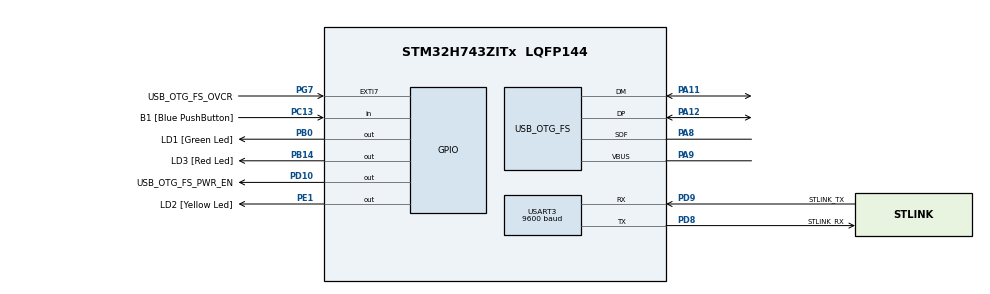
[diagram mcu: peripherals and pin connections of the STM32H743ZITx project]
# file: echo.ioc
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Mcu.Family=STM32H7
Mcu.Name=STM32H743ZITx
Mcu.Package=LQFP144
NVIC.PriorityGroup=NVIC_PRIORITYGROUP_4
NVIC.USART3_IRQn=true\:0\:0\:false\:false\:true\:true\:true\:true
PA1.Signal=ETH_REF_CLK
PA11.Mode=Device_Only
PA11.Signal=USB_OTG_FS_DM
PA12.Mode=Device_Only
PA12.Signal=USB_OTG_FS_DP
PA2.Signal=ETH_MDIO
PA7.Signal=ETH_CRS_DV
PA8.Mode=Activate_SOF_FS
PA8.Signal=USB_OTG_FS_SOF
PA9.Mode=Activate_VBUS
PA9.Signal=USB_OTG_FS_VBUS
PB0.GPIO_Label=LD1 [Green Led]
PB0.Signal=GPIO_Output
PB13.Signal=ETH_TXD1
PB14.GPIO_Label=LD3 [Red Led]
PB14.Signal=GPIO_Output
PC1.Signal=ETH_MDC
PC13.GPIO_Label=B1 [Blue PushButton]
PC13.Signal=GPIO_Input
PC14-OSC32_IN\ (OSC32_IN).Mode=LSE-External-Oscillator
PC14-OSC32_IN\ (OSC32_IN).Signal=RCC_OSC32_IN
PC15-OSC32_OUT\ (OSC32_OUT).Mode=LSE-External-Oscillator
PC15-OSC32_OUT\ (OSC32_OUT).Signal=RCC_OSC32_OUT
PC4.Signal=ETH_RXD0
PC5.Signal=ETH_RXD1
PD10.GPIO_Label=USB_OTG_FS_PWR_EN
PD10.Signal=GPIO_Output
PD8.GPIO_Label=STLINK_RX
PD8.Mode=Asynchronous
PD8.Signal=USART3_TX
PD9.GPIO_Label=STLINK_TX
PD9.Mode=Asynchronous
PD9.Signal=USART3_RX
PE1.GPIO_Label=LD2 [Yellow Led]
PE1.Signal=GPIO_Output
PG11.Signal=ETH_TX_EN
PG13.Signal=ETH_TXD0
PG7.GPIO_Label=USB_OTG_FS_OVCR
PG7.Signal=GPXTI7
PH0-OSC_IN\ (PH0).Mode=HSE-External-Clock-Source
PH0-OSC_IN\ (PH0).Signal=RCC_OSC_IN
PH1-OSC_OUT\ (PH1).Signal=RCC_OSC_OUT
ProjectManager.HeapSize=0x200
ProjectManager.StackSize=0x400
ProjectManager.TargetToolchain=STM32CubeIDE
RCC.ADCFreq_Value=16125000
RCC.APB1Freq_Value=64000000
RCC.APB2Freq_Value=64000000
RCC.APB3Freq_Value=64000000
RCC.APB4Freq_Value=64000000
RCC.CortexFreq_Value=64000000
RCC.DIVM1=1
RCC.DIVN1=24
RCC.DIVQ1=4
RCC.HCLKFreq_Value=64000000
RCC.HSE_VALUE=8000000
RCC.PLLFRACN=0
RCC.PWR_Regulator_Voltage_Scale=PWR_REGULATOR_VOLTAGE_SCALE2
RCC.SYSCLKFreq_VALUE=64000000
RCC.USBFreq_Value=48000000
USART3.BaudRate=9600
USART3.VirtualMode-Asynchronous=VM_ASYNC
USB_OTG_FS.VirtualMode=Device_Only
VP_MEMORYMAP_VS_MEMORYMAP.Mode=CurAppReg
board=NUCLEO-H743ZI2

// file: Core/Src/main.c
/* USER CODE BEGIN Header */
/**
  ******************************************************************************
  * @file           : main.c
  * @brief          : Main program body
  ******************************************************************************
  * @attention
  *
  * Copyright (c) 2024 STMicroelectronics.
  * All rights reserved.
  *
  * This software is licensed under terms that can be found in the LICENSE file
  * in the root directory of this software component.
  * If no LICENSE file comes with this software, it is provided AS-IS.
  *
  ******************************************************************************
  */
/* USER CODE END Header */
#include "main.h"
#include "memorymap.h"
#include "usart.h"
#include "usb_otg.h"
#include "gpio.h"

/* USER CODE BEGIN Includes */
#include "ESPE_USART_0.h"
/* USER CODE END Includes */

void SystemClock_Config(void);

int main(void)
{

  /* MCU Configuration--------------------------------------------------------*/

  /* Reset of all peripherals, Initializes the Flash interface and the Systick. */
  HAL_Init();

  /* Configure the system clock */
  SystemClock_Config();

  /* Initialize all configured peripherals */
  MX_GPIO_Init();
  MX_USART3_UART_Init();
  MX_USB_OTG_FS_PCD_Init();
  /* USER CODE BEGIN 2 */
  inizializzo_USART();
  create_vec();
  /* USER CODE END 2 */

  /* Infinite loop */
  while (1)
  {

  }
}

void SystemClock_Config(void)
{
  RCC_OscInitTypeDef RCC_OscInitStruct = {0};
  RCC_ClkInitTypeDef RCC_ClkInitStruct = {0};

  /** Supply configuration update enable
  */
  HAL_PWREx_ConfigSupply(PWR_LDO_SUPPLY);

  /** Configure the main internal regulator output voltage
  */
  __HAL_PWR_VOLTAGESCALING_CONFIG(PWR_REGULATOR_VOLTAGE_SCALE2);

  while(!__HAL_PWR_GET_FLAG(PWR_FLAG_VOSRDY)) {}

  /** Initializes the RCC Oscillators according to the specified parameters
  * in the RCC_OscInitTypeDef structure.
  */
  RCC_OscInitStruct.OscillatorType = RCC_OSCILLATORTYPE_HSI|RCC_OSCILLATORTYPE_HSE;
  RCC_OscInitStruct.HSEState = RCC_HSE_BYPASS;
  RCC_OscInitStruct.HSIState = RCC_HSI_DIV1;
  RCC_OscInitStruct.HSICalibrationValue = RCC_HSICALIBRATION_DEFAULT;
  RCC_OscInitStruct.PLL.PLLState = RCC_PLL_ON;
  RCC_OscInitStruct.PLL.PLLSource = RCC_PLLSOURCE_HSE;
  RCC_OscInitStruct.PLL.PLLM = 1;
  RCC_OscInitStruct.PLL.PLLN = 24;
  RCC_OscInitStruct.PLL.PLLP = 2;
  RCC_OscInitStruct.PLL.PLLQ = 4;
  RCC_OscInitStruct.PLL.PLLR = 2;
  RCC_OscInitStruct.PLL.PLLRGE = RCC_PLL1VCIRANGE_3;
  RCC_OscInitStruct.PLL.PLLVCOSEL = RCC_PLL1VCOWIDE;
  RCC_OscInitStruct.PLL.PLLFRACN = 0;
  if (HAL_RCC_OscConfig(&RCC_OscInitStruct) != HAL_OK)
  {
    Error_Handler();
  }

  /** Initializes the CPU, AHB and APB buses clocks
  */
  RCC_ClkInitStruct.ClockType = RCC_CLOCKTYPE_HCLK|RCC_CLOCKTYPE_SYSCLK
                              |RCC_CLOCKTYPE_PCLK1|RCC_CLOCKTYPE_PCLK2
                              |RCC_CLOCKTYPE_D3PCLK1|RCC_CLOCKTYPE_D1PCLK1;
  RCC_ClkInitStruct.SYSCLKSource = RCC_SYSCLKSOURCE_HSI;
  RCC_ClkInitStruct.SYSCLKDivider = RCC_SYSCLK_DIV1;
  RCC_ClkInitStruct.AHBCLKDivider = RCC_HCLK_DIV1;
  RCC_ClkInitStruct.APB3CLKDivider = RCC_APB3_DIV1;
  RCC_ClkInitStruct.APB1CLKDivider = RCC_APB1_DIV1;
  RCC_ClkInitStruct.APB2CLKDivider = RCC_APB2_DIV1;
  RCC_ClkInitStruct.APB4CLKDivider = RCC_APB4_DIV1;

  if (HAL_RCC_ClockConfig(&RCC_ClkInitStruct, FLASH_LATENCY_1) != HAL_OK)
  {
    Error_Handler();
  }
}

void Error_Handler(void)
{
  __disable_irq();
  while (1)
  {
  }
}
